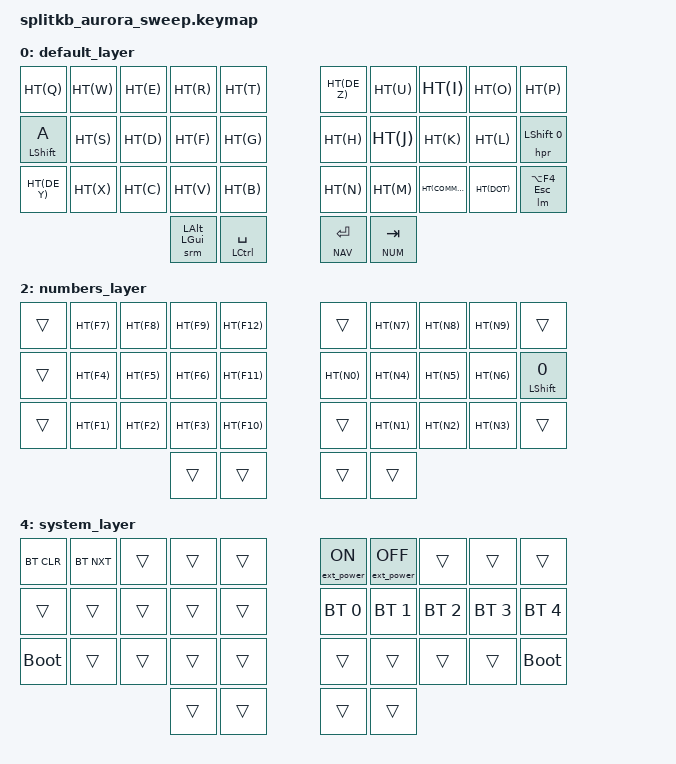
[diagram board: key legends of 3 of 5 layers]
/*
 * Copyright (c) 2020 The ZMK Contributors
 *
 * SPDX-License-Identifier: MIT
 */

#include <behaviors.dtsi>
#include <dt-bindings/zmk/keys.h>
#include <dt-bindings/zmk/bt.h>
#include <dt-bindings/zmk/outputs.h>
#include <dt-bindings/zmk/ext_power.h>
#include <dt-bindings/led/led.h>
#include <dt-bindings/zmk/backlight.h>
#include <dt-bindings/zmk/rgb.h>
#include <dt-bindings/zmk/reset.h>

#include "../zmk-nodefree-config/helper.h"
#include "mouse.dtsi"
#include "symbols.h"
#include "../zmk-nodefree-config/keypos_def/keypos_34keys.h"

#define DEFAULT 0
#define NAV 1
#define NUM 2
#define SYM 3
#define SYS 4

ZMK_BEHAVIOR(paste_above, macro,
    wait-ms = <0>;
    tap-ms = <1>;
    bindings = <&macro_press &kp LSHFT &kp LALT>
             , <&macro_tap &kp UP>
             , <&macro_release &kp LSHFT &kp LALT>;
)
ZMK_BEHAVIOR(paste_below, macro,
    wait-ms = <0>;
    tap-ms = <1>;
    bindings = <&macro_press &kp LSHFT &kp LALT>
             , <&macro_tap &kp DOWN>
             , <&macro_release &kp LSHFT &kp LALT>;
)
ZMK_BEHAVIOR(swapper3, macro,
    wait-ms = <30>;
    tap-ms = <10>;
    bindings = <&macro_press &mo NAV &kp LALT>
             , <&macro_tap &kp TAB>
             , <&macro_pause_for_release>
             , <&macro_release &mo NAV &kp LALT>;
)
ZMK_BEHAVIOR(swapper4, macro,
    wait-ms = <30>;
    tap-ms = <10>;
    bindings = <&macro_press &mo NAV &kp LCTRL>
             , <&macro_tap &kp TAB>
             , <&macro_pause_for_release>
             , <&macro_release &mo NAV &kp LCTRL>;
)

ZMK_BEHAVIOR(hrm, hold_tap,
    flavor = "balanced";
    tapping-term-ms = <280>;
    quick-tap-ms = <175>;
    bindings = <&kp>, <&kp>;
    hold-while-undecided;
)

ZMK_BEHAVIOR(srm, hold_tap,
    flavor = "balanced";
    tapping-term-ms = <250>;
    quick-tap-ms = <175>;
    bindings = <&kp>, <&sk>;
)

ZMK_BEHAVIOR(hpr, hold_tap,
    flavor = "balanced";
    tapping-term-ms = <280>;
    quick-tap-ms = <175>;
    bindings = <&kp>, <&smart_bspc>;
    hold-while-undecided;
)

ZMK_BEHAVIOR(lm, hold_tap,
    flavor = "tap-preferred";
    tapping-term-ms = <280>;
    quick-tap-ms = <175>;
    bindings = <&kp>, <&kp>;
)

#define ARROWKEYS LM1 LM2 LM3 LT2

// Alt+Tab swapper, requires PR #1366
ZMK_BEHAVIOR(swapper, tri_state,
    bindings = <&kt LALT>, <&kp TAB>, <&kt LALT>;
    ignored-key-positions = <ARROWKEYS>;
)
ZMK_BEHAVIOR(swapper2, tri_state,
    bindings = <&kt LCTRL>, <&kp TAB>, <&kt LCTRL>;
    ignored-key-positions = <ARROWKEYS>;
)

// Custom Combos
#undef COMBO_TERM
#define COMBO_TERM 40

// use require-prior-idle-ms for combos
#undef COMBO_HOOK
#define COMBO_HOOK require-prior-idle-ms = <150>;

#define ______ &trans
#define HT(key) &lm LC(key) key

ZMK_BEHAVIOR(smart_bspc, mod_morph,
    bindings = <&kp BSPC>, <&kp DEL>;
    mods = <(MOD_LSFT)>;
)

ZMK_COMBO(sz,  &kp DE_SZ, LM3 RT0, ALL)
ZMK_COMBO(ue, &kp DE_UE, RT1 LT2, ALL)
ZMK_COMBO(ae, &kp DE_AE, LM4 LT2, ALL)
ZMK_COMBO(oe, &kp DE_OE, RT3 LT2, ALL)
ZMK_COMBO(sys_layer_right, &mo 4, RH1 RH0, ALL)
ZMK_COMBO(sys_layer_left, &mo 4, LH1 LH0, ALL)
ZMK_COMBO(nav_layer, &to NAV, LH0 RH0, ALL)
ZMK_COMBO(home_layer, &to DEFAULT, LM1 LM3, ALL)
ZMK_COMBO(num_layer, &to NUM, LM1 LM2, ALL)

ZMK_COMBO(p_above, &paste_above, LB1 RT2, ALL)
ZMK_COMBO(p_below, &paste_below, LB1 RM2, ALL)
ZMK_COMBO(caps_word, &caps_word, RM1 RM2, ALL)

ZMK_COMBO(labk, HT(DE_LN_LABK), RH0 LM4, ALL)
ZMK_COMBO(lbrace, HT(LBRACE), RH0 LM3, ALL)
ZMK_COMBO(lbracket, HT(LBRACKET), RH0 LM2, ALL)
ZMK_COMBO(lprn, HT(DE_LN_LPRN), RH0 LM1, ALL)

ZMK_COMBO(rabk, HT(DE_LN_RABK), LH0 RM4, ALL)
ZMK_COMBO(rbrace, HT(RBRACE), LH0 RM3, ALL)
ZMK_COMBO(rbracket, HT(RBRACKET), LH0 RM2, ALL)
ZMK_COMBO(rprn, HT(DE_LN_RPRN), LH0 RM1, ALL)

ZMK_COMBO(dash, HT(FSLH), LM2 LM3, ALL)
ZMK_COMBO(plus, HT(DE_PLUS), LB2 LB3, ALL)
ZMK_COMBO(underscore, HT(LS(FSLH)), RM2 RM3, ALL)
ZMK_COMBO(slash, HT(DE_SLSH), RT1 RT2, ALL)
ZMK_COMBO(bslash, HT(DE_BSLH), RT0 RT1, ALL)
ZMK_COMBO(asterix, HT(DE_ASTR), RB1 RB2, ALL)
ZMK_COMBO(is, HT(DE_EQL), RT2 LM3, ALL)
ZMK_COMBO(hash, HT(DE_HASH), RM0 LM3, ALL)
ZMK_COMBO(at, HT(RA(Q)), LM4 LT0, ALL)
ZMK_COMBO(and, HT(DE_AMPR), LM4 RB0, ALL)
ZMK_COMBO(or, HT(DE_PIPE), RT3 LT1, ALL)
ZMK_COMBO(exclam, HT(DE_EXCL), LT3 LT2, ALL)
ZMK_COMBO(ques, HT(DE_QUES), RT3 RT2, ALL)
ZMK_COMBO(dollar, HT(DE_DLR), LM2 RT3, ALL)
ZMK_COMBO(squot, HT(DE_QUOT), RM3 RM4, ALL)
ZMK_COMBO(dquot, HT(DE_DQUO), LM3 LM4, ALL)
ZMK_COMBO(grave, HT(GRAVE), LT1 LM0, ALL)
ZMK_COMBO(percent, HT(DE_PERC), LT1 LT2, ALL)
ZMK_COMBO(degree, HT(DE_DEG), LT4 LT3, ALL)
ZMK_COMBO(shift, &kp LSHFT,LM1 LM2 LM3, ALL)


ZMK_LAYER(default_layer,
  // ╭─────────────┬─────────────┬─────────────┬─────────────┬─────────────╮   ╭─────────────┬─────────────┬─────────────┬─────────────┬─────────────╮
       HT(Q)         HT(W)         HT(E)         HT(R)         HT(T)             HT(DE_Z)      HT(U)         HT(I)         HT(O)         HT(P)
  // ├─────────────┼─────────────┼─────────────┼─────────────┼─────────────┤   ├─────────────┼─────────────┼─────────────┼─────────────┼─────────────┤
      &hrm LSHFT A   HT(S)         HT(D)         HT(F)         HT(G)             HT(H)         HT(J)         HT(K)         HT(L)         &hpr LSHFT 0
  // ├─────────────┼─────────────┼─────────────┼─────────────┼─────────────┤   ├─────────────┼─────────────┼─────────────┼─────────────┼─────────────┤
      HT(DE_Y)      HT(X)         HT(C)         HT(V)         HT(B)             HT(N)         HT(M)         HT(COMMA)     HT(DOT)     &lm LA(F4) ESC
  // ╰─────────────┼─────────────┼─────────────┼─────────────┼─────────────┤   ├─────────────┼─────────────┼─────────────┼─────────────┼─────────────╯
                                              &srm LALT LGUI &hrm LCTRL SPACE   &lt NAV RET   &lt NUM TAB
  //                                           ╰─────────────┴─────────────╯   ╰─────────────┴─────────────╯
)

ZMK_LAYER(nav_layer,
  // ╭─────────────┬─────────────┬─────────────┬─────────────┬─────────────╮   ╭─────────────┬─────────────┬─────────────┬─────────────┬─────────────╮
       U_WH_L        HT(PG_UP)     &kp UP        HT(PG_DN)     U_WH_R            U_WH_L        U_WH_U        U_MS_U        U_WH_D        U_WH_R
  // ├─────────────┼─────────────┼─────────────┼─────────────┼─────────────┤   ├─────────────┼─────────────┼─────────────┼─────────────┼─────────────┤
       ______       &lm HOME LEFT  &kp DOWN     &lm END RIGHT  ______            ______        U_MS_L        U_MS_D         U_MS_R       ______
  // ├─────────────┼─────────────┼─────────────┼─────────────┼─────────────┤   ├─────────────┼─────────────┼─────────────┼─────────────┼─────────────┤
       &swapper2      U_BTN3        U_BTN2        U_BTN1        &swapper    &kp C_VOLUME_DOWN &kp C_PREVIOUS &kp C_PLAY_PAUSE &kp C_NEXT &kp C_VOLUME_UP
  // ╰─────────────┼─────────────┼─────────────┼─────────────┼─────────────┤   ├─────────────┼─────────────┼─────────────┼─────────────┼─────────────╯
                                                 ______        ______            ______        ______
  //                                           ╰─────────────┴─────────────╯   ╰─────────────┴─────────────╯
)

ZMK_LAYER(numbers_layer,
  // ╭─────────────┬─────────────┬─────────────┬─────────────┬─────────────╮   ╭─────────────┬─────────────┬─────────────┬─────────────┬─────────────╮
       ______        HT(F7)        HT(F8)        HT(F9)        HT(F12)           ______        HT(N7)        HT(N8)        HT(N9)        ______
  // ├─────────────┼─────────────┼─────────────┼─────────────┼─────────────┤   ├─────────────┼─────────────┼─────────────┼─────────────┼─────────────┤
       ______        HT(F4)        HT(F5)        HT(F6)        HT(F11)           HT(N0)        HT(N4)        HT(N5)        HT(N6)       &hrm LSHFT N0
  // ├─────────────┼─────────────┼─────────────┼─────────────┼─────────────┤   ├─────────────┼─────────────┼─────────────┼─────────────┼─────────────┤
       ______        HT(F1)        HT(F2)        HT(F3)        HT(F10)            ______        HT(N1)        HT(N2)        HT(N3)        ______
  // ╰─────────────┼─────────────┼─────────────┼─────────────┼─────────────┤   ├─────────────┼─────────────┼─────────────┼─────────────┼─────────────╯
                                                 ______        ______            ______        ______
  //                                           ╰─────────────┴─────────────╯   ╰─────────────┴─────────────╯
)

ZMK_LAYER(symbols_layer,
  // ╭─────────────┬─────────────┬─────────────┬─────────────┬─────────────┬─────────────╮   ╭─────────────┬─────────────┬─────────────┬─────────────┬─────────────┬─────────────╮
       HT(RA(Q))     HT(DE_EXCL)   HT(DE_DQUO)   HT(DE_DLR)    HT(DE_PERC)   HT(DE_DEG)        HT(DE_AMPR)   HT(DE_SLSH)   HT(DE_QUOT)   HT(DE_EQL)    HT(DE_QUES)   HT(DE_ASTR)
  // ├─────────────┼─────────────┼─────────────┼─────────────┼─────────────┼─────────────┤   ├─────────────┼─────────────┼─────────────┼─────────────┼─────────────┼─────────────┤
       HT(GRAVE)     HT(DE_LN_LABK) HT(LBRACE)    HT(LBRACKET) HT(DE_LN_LPRN) ______            ______     HT(DE_LN_RPRN)  HT(RBRACKET)  HT(RBRACE)   HT(DE_LN_RABK) HT(DE_HASH)
  // ├─────────────┼─────────────┼─────────────┼─────────────┼─────────────┼─────────────┤   ├─────────────┼─────────────┼─────────────┼─────────────┼─────────────┼─────────────┤
       HT(DE_PIPE)   ______        ______        ______        ______        ______            ______        ______        ______        ______        ______        HT(DE_PLUS)
  // ╰─────────────┼─────────────┼─────────────┼─────────────┼─────────────┼─────────────┤   ├─────────────┼─────────────┼─────────────┼─────────────┼─────────────┼─────────────╯
                                                 ______        ______        ______            ______        ______        ______
  //                                           ╰─────────────┴─────────────┴─────────────╯   ╰─────────────┴─────────────┴─────────────╯
)

ZMK_LAYER(system_layer,
  // ╭─────────────┬─────────────┬─────────────┬─────────────┬─────────────╮  ╭─────────────┬─────────────┬─────────────┬─────────────┬─────────────╮
       &bt BT_CLR    &bt BT_NXT    ______        ______        ______          &ext_power EP_ON &ext_power EP_OFF ______       ______        ______
  // ├─────────────┼─────────────┼─────────────┼─────────────┼─────────────┤  ├─────────────┼─────────────┼─────────────┼─────────────┼─────────────┤
       ______        ______        ______        ______        ______           &bt BT_SEL 0  &bt BT_SEL 1  &bt BT_SEL 2  &bt BT_SEL 3  &bt BT_SEL 4
  // ├─────────────┼─────────────┼─────────────┼─────────────┼─────────────┤  ├─────────────┼─────────────┼─────────────┼─────────────┼─────────────┤
       &bootloader   ______        ______        ______        ______           ______        ______        ______        ______        &bootloader
  // ╰─────────────┼─────────────┼─────────────┼─────────────┼─────────────┤  ├─────────────┼─────────────┼─────────────┼─────────────┼─────────────╯
                                                 ______        ______           ______        ______
  //                                           ╰─────────────┴─────────────╯  ╰─────────────┴─────────────╯
)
